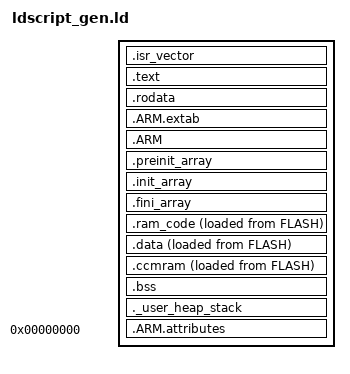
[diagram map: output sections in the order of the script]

/* Entry Point */
ENTRY(Reset_Handler)

/* Highest address of the user mode stack */
_estack = ORIGIN(RAM_DATA) + LENGTH(RAM_DATA) - 0x80;
/* Reserve some RAM to exchange data for bootloader */
_bootloader_data = ORIGIN(RAM_DATA) + LENGTH(RAM_DATA) - 0x7C;
/* Generate a link error if heap and stack don't fit into RAM */
_Min_Heap_Size = 0x200;   /* required amount of heap  */
_Min_Stack_Size = 0x1000; /* required amount of stack */
_Min_BL_Size = 0x80;      /* required amount of bootloader data */

/* Define output sections */
SECTIONS
{
  /* The startup code goes first into FLASH */
  .isr_vector :
  {
    . = ALIGN(4);
    KEEP(*(.isr_vector)) /* Startup code */
    . = ALIGN(4);
  } >FLASH

  /* The program code and other data goes into FLASH */
  .text :
  {
    . = ALIGN(4);
    *(.text)           /* .text sections (code) */
    *(.text*)          /* .text* sections (code) */
    *(.glue_7)         /* glue arm to thumb code */
    *(.glue_7t)        /* glue thumb to arm code */
    *(.eh_frame)

    KEEP (*(.init))
    KEEP (*(.fini))

    . = ALIGN(4);
    _etext = .;        /* define a global symbols at end of code */
  } >FLASH

  /* Constant data goes into FLASH */
  .rodata :
  {
    . = ALIGN(4);
    *(.rodata)         /* .rodata sections (constants, strings, etc.) */
    *(.rodata*)        /* .rodata* sections (constants, strings, etc.) */
    . = ALIGN(4);
  } >FLASH

  .ARM.extab   : { *(.ARM.extab* .gnu.linkonce.armextab.*) } >FLASH
  .ARM : {
    __exidx_start = .;
    *(.ARM.exidx*)
    __exidx_end = .;
  } >FLASH

  .preinit_array     :
  {
    PROVIDE_HIDDEN (__preinit_array_start = .);
    KEEP (*(.preinit_array*))
    PROVIDE_HIDDEN (__preinit_array_end = .);
  } >FLASH
  .init_array :
  {
    PROVIDE_HIDDEN (__init_array_start = .);
    KEEP (*(SORT(.init_array.*)))
    KEEP (*(.init_array*))
    PROVIDE_HIDDEN (__init_array_end = .);
  } >FLASH
  .fini_array :
  {
    PROVIDE_HIDDEN (__fini_array_start = .);
    KEEP (*(SORT(.fini_array.*)))
    KEEP (*(.fini_array*))
    PROVIDE_HIDDEN (__fini_array_end = .);
  } >FLASH

  /* Critical program code goes into RAM_CODE */
  ram_code = LOADADDR(.ram_code);
  .ram_code :
  {
    . = ALIGN(4);
    ram_code_start = .;
    *(.ram_code)
    *(.ram_code*)
    . = ALIGN(4);
    ram_code_end = .;
  } >RAM_CODE AT> FLASH

  /* used by the startup to initialize data */
  _sidata = LOADADDR(.data);

  /* Initialized data sections goes into RAM, load LMA copy after code */
  .data :
  {
    . = ALIGN(4);
    _sdata = .;        /* create a global symbol at data start */
    *(.data)           /* .data sections */
    *(.data*)          /* .data* sections */

    . = ALIGN(4);
    _edata = .;        /* define a global symbol at data end */
  } >RAM_DATA AT> FLASH

  _siccmram = LOADADDR(.ccmram);

  /* CCM-RAM section
  *
  * IMPORTANT NOTE!
  * If initialized variables will be placed in this section,
  * the startup code needs to be modified to copy the init-values.
  */
  .ccmram :
  {
    . = ALIGN(4);
    _sccmram = .;       /* create a global symbol at ccmram start */
    *(.ccmram)
    *(.ccmram*)

    . = ALIGN(4);
    _eccmram = .;       /* create a global symbol at ccmram end */
  } >CCMRAM AT> FLASH

  /* Uninitialized data section */
  . = ALIGN(4);
  .bss (NOLOAD) :
  {
    /* This is used by the startup in order to initialize the .bss secion */
    _sbss = .;         /* define a global symbol at bss start */
    __bss_start__ = _sbss;
    *(.bss)
    *(.bss*)
    *(COMMON)

    . = ALIGN(4);
    _ebss = .;         /* define a global symbol at bss end */
    __bss_end__ = _ebss;
  } >RAM_DATA

  /* User_heap_stack section, used to check that there is enough RAM left */
  ._user_heap_stack (NOLOAD) :
  {
    . = ALIGN(8);
    PROVIDE ( end = . );
    PROVIDE ( _end = . );
    . = . + _Min_Heap_Size;
    . = . + _Min_Stack_Size;
    . = . + _Min_BL_Size;
    . = ALIGN(8);
  } >RAM_DATA

  /* Remove information from the standard libraries */
  /DISCARD/ :
  {
    libc.a ( * )
    libm.a ( * )
    libgcc.a ( * )
  }

  .ARM.attributes 0 : { *(.ARM.attributes) }
}
